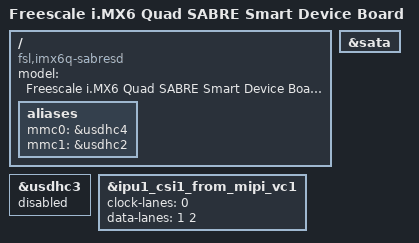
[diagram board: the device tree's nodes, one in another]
// SPDX-License-Identifier: GPL-2.0+
//
// Copyright 2012 Freescale Semiconductor, Inc.
// Copyright 2011 Linaro Ltd.

/dts-v1/;

#include "imx6q.dtsi"
#include "imx6qdl-sabresd.dtsi"

/ {
	model = "Freescale i.MX6 Quad SABRE Smart Device Board";
	compatible = "fsl,imx6q-sabresd", "fsl,imx6q";
	aliases {
		mmc0 = &usdhc4;
		mmc1 = &usdhc2;
	};
};

&sata {
	status = "okay";
};
&usdhc3 {
	status = "disable";
};

&ipu1_csi1_from_mipi_vc1 {
	clock-lanes = <0>;
	data-lanes = <1 2>;
};
